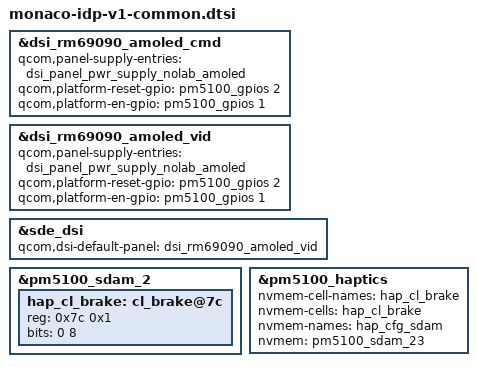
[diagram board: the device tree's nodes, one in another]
#include "monaco-thermal-overlay.dtsi"
#include "monaco-haptics-fifo-data.dtsi"

&dsi_rm69090_amoled_cmd {
	qcom,panel-supply-entries = <&dsi_panel_pwr_supply_nolab_amoled>;
	qcom,platform-reset-gpio = <&pm5100_gpios 2 0>;
	qcom,platform-en-gpio = <&pm5100_gpios 1 0>;
};

&dsi_rm69090_amoled_vid {
	qcom,panel-supply-entries = <&dsi_panel_pwr_supply_nolab_amoled>;
	qcom,platform-reset-gpio = <&pm5100_gpios 2 0>;
	qcom,platform-en-gpio = <&pm5100_gpios 1 0>;
};

&sde_dsi {
	qcom,dsi-default-panel = <&dsi_rm69090_amoled_vid>;
};

&pm5100_sdam_2 {
	hap_cl_brake: cl_brake@7c {
		reg = <0x7c 0x1>;
		bits = <0 8>;
	};
};

&pm5100_haptics {
	nvmem-cell-names = "hap_cl_brake";
	nvmem-cells = <&hap_cl_brake>;
	nvmem-names = "hap_cfg_sdam";
	nvmem = <&pm5100_sdam_23>;
	status = "okay";
};
